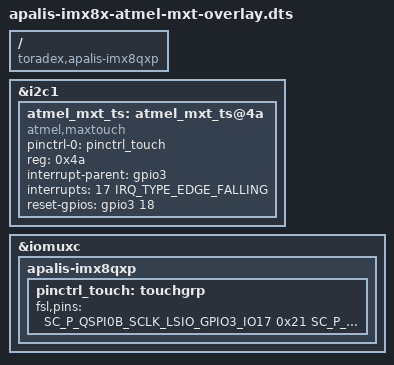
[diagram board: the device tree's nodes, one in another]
// Atmel MXT touchscreen for the 7inch and 10inch display orderable at Toradex.

/dts-v1/;
/plugin/;

#include "dt-bindings/interrupt-controller/irq.h"
#include "dt-bindings/gpio/gpio.h"
#include "dt-bindings/pinctrl/pads-imx8qxp.h"

/ {
	compatible = "toradex,apalis-imx8qxp";
	fragment@0 {
		target = <&i2c1>;
		__overlay__ {
			/* Atmel maxtouch controller */
			atmel_mxt_ts: atmel_mxt_ts@4a {
				compatible = "atmel,maxtouch";
				pinctrl-names = "default";
				pinctrl-0 = <&pinctrl_touch>;
				reg = <0x4a>;
				interrupt-parent = <&gpio3>;
				interrupts = <17 IRQ_TYPE_EDGE_FALLING>;    /* Apalis GPIO5 */
				reset-gpios = <&gpio3 18 GPIO_ACTIVE_HIGH>; /* Apalis GPIO6 */
				status = "okay";
			};
		};
	};

	fragment@1 {
		target = <&iomuxc>;
		__overlay__ {
			apalis-imx8qxp {
				/* Apalis GPIO5+6 */
				pinctrl_touch: touchgrp {
					fsl,pins = <
						SC_P_QSPI0B_SCLK_LSIO_GPIO3_IO17		0x21		/* MXM3 11 */
						SC_P_QSPI0B_DATA0_LSIO_GPIO3_IO18		0x21		/* MXM3 13 */
					>;
				};
			};
		};
	};
};
